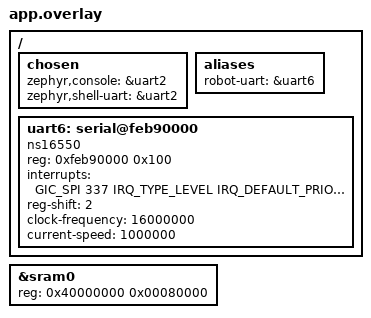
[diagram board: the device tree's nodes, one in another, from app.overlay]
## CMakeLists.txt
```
cmake_minimum_required(VERSION 3.20.0)
find_package(Zephyr REQUIRED HINTS $ENV{ZEPHYR_BASE})
project(orangepi_robot_control)

target_include_directories(app PRIVATE ${CMAKE_CURRENT_LIST_DIR}/../../protocol)

target_sources(app PRIVATE
  src/main.c
  src/ivc_transport.c
  src/robot_config_receiver.c
  src/feetech_bus.c
  src/robot_controller.c
  src/resettable_watchdog.c
)
```

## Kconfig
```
mainmenu "Orange Pi robot control"

source "Kconfig.zephyr"

config ROBOT_STATUS_EVERY_MESSAGES
	int "Valid IVC messages per combined status report"
	default 60
	range 0 1000000
	help
	  Print one combined receive, control-rate and latest-perception status
	  after this many valid IVC messages. Set to 0 to disable the report.

config ROBOT_CONTROL_ALIVE_LOG
	bool "Print an independent robot-control alive heartbeat"
	default n
	help
	  Print ZEPHYR_ROBOT_CONTROL_ALIVE every 10 seconds even when no IVC
	  messages arrive. The combined message-count status is normally enough.
```

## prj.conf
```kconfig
CONFIG_PRINTK=y
CONFIG_SERIAL=y
CONFIG_UART_NS16550=y
CONFIG_UART_NS16550_ACCESS_WORD_ONLY=y
CONFIG_MAIN_STACK_SIZE=8192
CONFIG_SYSTEM_WORKQUEUE_STACK_SIZE=4096
CONFIG_SYS_CLOCK_EXISTS=y
CONFIG_ARM_ARCH_TIMER=y
CONFIG_AXIVC=y
CONFIG_AXIVC_AXVISOR_HVC=y
CONFIG_AXIVC_FALLBACK_POLL_MS=1
CONFIG_AXIVC_MAX_CHANNELS=1

CONFIG_ROBOT_STATUS_EVERY_MESSAGES=60
CONFIG_ROBOT_CONTROL_ALIVE_LOG=n

# Keep exceptional watchdog, controller and UART diagnostics deferred rather
# than synchronously writing the virtual console while a controller/UART lock
# is held. Routine Feetech and arm-work sampling is intentionally disabled.
CONFIG_LOG=y
CONFIG_LOG_MODE_DEFERRED=y
CONFIG_LOG_DEFAULT_LEVEL=1
CONFIG_LOG_RUNTIME_DEFAULT_LEVEL=4
CONFIG_LOG_BUFFER_SIZE=8192
CONFIG_LOG_PROCESS_THREAD=y
CONFIG_LOG_PROCESS_THREAD_STACK_SIZE=2048
CONFIG_LOG_PRINTK=n

# Keep the interactive terminal on AxVisor's AArch64 PL011 virtual console.
# UART6 remains dedicated to the 1 Mbps Feetech bus selected by robot-uart.
CONFIG_SHELL=y
CONFIG_SHELL_MINIMAL=y
CONFIG_SHELL_BACKEND_SERIAL=y
CONFIG_SHELL_PROMPT_UART="zephyr:~$ "
CONFIG_KERNEL_SHELL=y
CONFIG_DEVICE_SHELL=y
```

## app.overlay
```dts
/ {
	chosen {
		/* AxVisor owns the physical UART2 console and turns the host-selected
		 * UART2 into an emulated console for this virtualized guest, so Zephyr
		 * must keep using the board's default uart2 node.  Do not list UART2 in
		 * the guest passthrough set: only UART6 is passed through physically.
		 */
		zephyr,console = &uart2;
		zephyr,shell-uart = &uart2;
	};

	aliases {
		robot-uart = &uart6;
	};

	uart6: serial@feb90000 {
		compatible = "ns16550";
		reg = <0xfeb90000 0x100>;
		interrupts = <GIC_SPI 337 IRQ_TYPE_LEVEL IRQ_DEFAULT_PRIORITY>;
		reg-shift = <2>;
		/* U-Boot prepares the UART6 fractional parent at 16 MHz.  An
		 * integer divisor of one then gives the Feetech bus' exact 1 Mbps
		 * rate, matching the board's working Linux configuration.
		 */
		clock-frequency = <16000000>;
		current-speed = <1000000>;
		status = "okay";
	};
};

/* The fixed control workload needs no dynamic bulk RAM.  Keep Zephyr's own
 * page-frame ontology small; AxVisor still reserves a 128 MiB isolation slot.
 */
&sram0 {
	reg = <0x40000000 0x00080000>;
};
```

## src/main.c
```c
/* SPDX-License-Identifier: Apache-2.0 */

#include "feetech_bus.h"
#include "ivc_transport.h"
#include "perception_result_v2.h"
#include "resettable_watchdog.h"
#include "robot_config_receiver.h"
#include "robot_controller.h"

#include <zephyr/device.h>
#include <zephyr/drivers/uart.h>
#include <zephyr/kernel.h>
#include <zephyr/logging/log.h>
#include <zephyr/sys/printk.h>
#include <zephyr/sys/util.h>

#include <errno.h>
#include <stdbool.h>
#include <stdint.h>

#define ROBOT_UART_NODE DT_ALIAS(robot_uart)
#define ARM_INTERPOLATION_PERIOD_MS 50U
#define IVC_IDLE_POLL_MS 1U
#define IVC_RECONNECT_IDLE_MS 1500U
#define STARTUP_SETTLE_MS 30000U
#define HEARTBEAT_MS 10000U
#define FEETECH_UART_BAUD 1000000U
#define SLOW_CONTROLLER_LOCK_MS 5U
#define SLOW_CONTROL_PROCESS_MS 20U

LOG_MODULE_REGISTER(robot_control_diag, LOG_LEVEL_DBG);

static const struct device *const robot_uart = DEVICE_DT_GET(ROBOT_UART_NODE);
static struct robot_controller controller;
static struct resettable_watchdog input_watchdog;
static struct k_timer arm_timer;
static struct k_work arm_work;
K_MUTEX_DEFINE(controller_lock);

static int64_t next_arm_deadline_ms;
static uint64_t arm_cycles;
static uint32_t max_arm_timer_late_ms;

BUILD_ASSERT(sizeof(struct perception_result_v2) == 48U);
BUILD_ASSERT(sizeof(struct robot_config_message_v1) == 48U);

static int receive_initial_config(struct robot_ivc *ivc,
				  struct robot_config_receiver *receiver,
				  struct robot_runtime_config_v1 *config)
{
	uint64_t idle_polls = 0U;

	printk("ZEPHYR_ROBOT_CONFIG_WAIT source=axvisor-ivc\n");
	for (;;) {
		struct robot_config_message_v1 message = {0};
		struct robot_config_message_v1 response = {0};
		size_t length = 0U;
		int status = robot_ivc_try_receive(ivc, &message, sizeof(message), &length);

		if (status == -EAGAIN) {
			if (++idle_polls % 1000U == 0U) {
				printk("ZEPHYR_ROBOT_CONFIG_WAIT polls=%llu\n", idle_polls);
			}
			k_msleep(IVC_IDLE_POLL_MS);
			continue;
		}
		if (status != 0) {
			printk("ZEPHYR_ROBOT_CONFIG_FAILED reason=receive status=%d\n",
			       status);
			return status;
		}
		if (!robot_config_is_message(&message, length)) {
			printk("ZEPHYR_ROBOT_CONFIG_DROP reason=expected-config len=%zu\n",
			       length);
			continue;
		}

		bool applied = false;
		robot_config_receiver_handle(receiver, &message, &response, config,
					     &applied);
		if (applied) {
			robot_config_receiver_mark_applied(receiver);
		}
		status = robot_ivc_send(ivc, &response, sizeof(response), 500);
		if (status != 0) {
			printk("ZEPHYR_ROBOT_CONFIG_FAILED reason=ack-send chunk=%u "
			       "status=%d\n", message.chunk_index, status);
			return status;
		}
		if (response.type == ROBOT_CONFIG_REJECTED) {
			printk("ZEPHYR_ROBOT_CONFIG_REJECTED session=%u chunk=%u "
			       "status=%u expected=%u\n", response.session_id,
			       response.chunk_index, response.status,
			       response.chunk_count);
		} else if (applied) {
			printk("ZEPHYR_ROBOT_CONFIG_APPLIED session=%u chunks=%u "
			       "crc=0x%08x speed_level=%u\n", response.session_id,
			       response.chunk_count, response.config_crc32,
			       config->motion_speed_level);
			return 0;
		} else {
			printk("ZEPHYR_ROBOT_CONFIG_ACK session=%u chunk=%u "
			       "next=%u\n", response.session_id,
			       response.chunk_index, response.chunk_count);
		}
	}
}

static void input_watchdog_handler(void *context)
{
	struct robot_controller *robot = context;
	const int64_t now_ms = k_uptime_get();
	const int64_t lock_started_ms = now_ms;

	LOG_DBG("ZEPHYR_DIAG component=watchdog event=handler-enter uptime_ms=%lld",
		now_ms);
	k_mutex_lock(&controller_lock, K_FOREVER);
	const int64_t lock_wait_ms = k_uptime_get() - lock_started_ms;
	const bool expired = robot_controller_input_timeout(robot, now_ms);
	if (!expired && robot->have_input) {
		/* An expiry work item can already be queued when a new frame resets
		 * the timer.  Recompute the remaining time so that this stale work
		 * item cannot cancel the new frame's deadline.  This also makes an
		 * early, tick-rounded callback harmless.
		 */
		const int64_t elapsed_ms = MAX(now_ms - robot->last_input_ms, 0);
		const uint32_t remaining_ms =
			ROBOT_INPUT_TIMEOUT_MS -
			(uint32_t)MIN(elapsed_ms, ROBOT_INPUT_TIMEOUT_MS - 1U);
		resettable_watchdog_restart(&input_watchdog, remaining_ms);
	}
	k_mutex_unlock(&controller_lock);
	LOG_DBG("ZEPHYR_DIAG component=watchdog event=handler-exit expired=%u "
		"lock_wait_ms=%lld elapsed_ms=%lld",
		expired, lock_wait_ms, k_uptime_get() - now_ms);
}

static void arm_work_handler(struct k_work *work)
{
	ARG_UNUSED(work);
	const int64_t now_ms = k_uptime_get();
	k_mutex_lock(&controller_lock, K_FOREVER);
	if (now_ms > next_arm_deadline_ms) {
		max_arm_timer_late_ms =
			MAX(max_arm_timer_late_ms,
			    (uint32_t)(now_ms - next_arm_deadline_ms));
	}
	do {
		next_arm_deadline_ms += ARM_INTERPOLATION_PERIOD_MS;
	} while (next_arm_deadline_ms <= now_ms);

	robot_controller_arm_tick(&controller, now_ms);
	++arm_cycles;
	k_mutex_unlock(&controller_lock);
}

static void arm_timer_expiry(struct k_timer *timer)
{
	ARG_UNUSED(timer);
	(void)k_work_submit(&arm_work);
}

static bool valid_result(const struct perception_result_v2 *result)
{
	return result->magic == PERCEPTION_MAGIC &&
	       result->version == PERCEPTION_VERSION &&
	       result->frame_width > 0U && result->frame_height > 0U;
}

int main(void)
{
	struct feetech_bus bus = {0};
	struct robot_ivc ivc = {0};
	struct robot_config_receiver config_receiver;
	struct robot_runtime_config_v1 runtime_config;
	uint16_t initial_arm[FEETECH_ARM_COUNT];
	uint64_t received = 0U;
	uint64_t processed = 0U;
	uint64_t invalid = 0U;
	uint64_t heartbeat = 0U;
	int64_t next_heartbeat_ms;
	bool status_window_active = false;
	int64_t status_window_started_ms = 0;
	uint64_t status_window_started_received = 0U;
	uint64_t status_window_started_processed = 0U;
	int status;

	printk("ZEPHYR_ROBOT_CONTROL_START protocol=2 source=axvisor-ivc uart=uart6\n");
	printk("ZEPHYR_TIMER_READY driver=arm_arch_timer tick_hz=%u\n",
	       CONFIG_SYS_CLOCK_TICKS_PER_SEC);
	printk("ZEPHYR_ROBOT_CONTROL_WAIT settle_ms=%u\n", STARTUP_SETTLE_MS);
	const int64_t startup_started_ms = k_uptime_get();
	k_msleep(STARTUP_SETTLE_MS);
	const int64_t startup_elapsed_ms = k_uptime_get() - startup_started_ms;
	printk("ZEPHYR_TIMER_WAKE phase=startup requested_ms=%u actual_ms=%lld\n",
	       STARTUP_SETTLE_MS, startup_elapsed_ms);

	status = feetech_bus_init(&bus, robot_uart);
	if (status != 0) {
		printk("ZEPHYR_ROBOT_CONTROL_FAILED reason=uart6-not-ready status=%d\n",
		       status);
		return 1;
	}
	const struct uart_config config = {
		/* 16 MHz input / (16 * DLL=1) = 1 Mbps. */
		.baudrate = FEETECH_UART_BAUD,
		.parity = UART_CFG_PARITY_NONE,
		.stop_bits = UART_CFG_STOP_BITS_1,
		.data_bits = UART_CFG_DATA_BITS_8,
		.flow_ctrl = UART_CFG_FLOW_CTRL_NONE,
	};
	status = uart_configure(robot_uart, &config);
	if (status != 0) {
		printk("ZEPHYR_ROBOT_CONTROL_FAILED reason=uart6-config status=%d\n",
		       status);
		return 1;
	}
	printk("ZEPHYR_UART6_READY clock_hz=16000000 baud=1000000 divisor=1 dlf=0\n");

	status = feetech_configure_wheels(&bus);
	if (status != 0) {
		return 1;
	}
	status = feetech_configure_arm(&bus, initial_arm);
	if (status != 0) {
		feetech_stop_wheels(&bus, "ARM_INIT_FAILED_STOP");
		printk("ZEPHYR_ROBOT_CONTROL_FAILED reason=arm-config status=%d\n", status);
		return 1;
	}
	status = robot_ivc_subscribe(&ivc);
	if (status != 0) {
		feetech_stop_wheels(&bus, "IVC_FAILED_STOP");
		printk("ZEPHYR_ROBOT_CONTROL_FAILED reason=ivc-subscribe status=%d\n", status);
		return 1;
	}
	robot_config_receiver_init(&config_receiver);
	status = receive_initial_config(&ivc, &config_receiver, &runtime_config);
	if (status != 0) {
		feetech_stop_wheels(&bus, "CONFIG_FAILED_STOP");
		feetech_arm_torque_off(&bus);
		(void)robot_ivc_close(&ivc);
		return 1;
	}
	status = robot_controller_init(&controller, &bus, &runtime_config);
	if (status != 0) {
		feetech_stop_wheels(&bus, "CONTROLLER_INIT_FAILED_STOP");
		(void)robot_ivc_close(&ivc);
		return 1;
	}
	resettable_watchdog_init(&input_watchdog, input_watchdog_handler,
				 &controller);
	k_work_init(&arm_work, arm_work_handler);
	k_timer_init(&arm_timer, arm_timer_expiry, NULL);
	next_arm_deadline_ms = k_uptime_get() + ARM_INTERPOLATION_PERIOD_MS;
	k_timer_start(&arm_timer, K_MSEC(ARM_INTERPOLATION_PERIOD_MS),
		      K_MSEC(ARM_INTERPOLATION_PERIOD_MS));
	printk("ZEPHYR_ROBOT_CONTROL_READY source=axvisor-ivc arm_period_ms=%u "
	       "ivc_poll_ms=%u watchdog_ms=%u watchdog=resettable-one-shot\n",
	       ARM_INTERPOLATION_PERIOD_MS, IVC_IDLE_POLL_MS,
	       ROBOT_INPUT_TIMEOUT_MS);
	next_heartbeat_ms = k_uptime_get() + HEARTBEAT_MS;

	for (;;) {
		struct perception_result_v2 newest;
		bool have_newest = false;
		bool transport_disconnected = false;
		const uint64_t received_before_poll = received;
		const uint64_t processed_before_poll = processed;

		for (;;) {
			union {
				struct perception_result_v2 perception;
				struct robot_config_message_v1 config;
				uint8_t bytes[ROBOT_CONFIG_MESSAGE_SIZE];
			} message = {0};
			size_t length = 0U;
			status = robot_ivc_try_receive(&ivc, message.bytes,
					       sizeof(message.bytes),
					       &length);
			if (status == -EAGAIN) {
				break;
			}
			if (status != 0) {
				++invalid;
				printk("ZEPHYR_IVC_DROP status=%d len=%zu invalid=%llu\n",
				       status, length,
				       invalid);
				transport_disconnected = true;
				break;
			}
			if (robot_config_is_message(message.bytes, length)) {
				struct robot_config_message_v1 response = {0};
				if (message.config.type == ROBOT_CONTROL_FINISH) {
					k_mutex_lock(&controller_lock, K_FOREVER);
					robot_controller_control_result(&controller,
						config_receiver.applied_session_id,
						config_receiver.applied_crc32, &message.config, &response);
					k_mutex_unlock(&controller_lock);
					/* The main loop is the sole reverse-ring producer. */
					status = robot_ivc_send(&ivc, &response, sizeof(response), 0);
					if (status != 0 && status != -EAGAIN && status != -ETIMEDOUT) {
						printk("ZEPHYR_CONTROL_RESULT_SEND_FAILED status=%d\n", status);
					}
					continue;
				}
				struct robot_runtime_config_v1 candidate = {0};
				bool applied = false;
				bool ready = true;

				if (message.config.type == ROBOT_CONFIG_BEGIN) {
					k_mutex_lock(&controller_lock, K_FOREVER);
					ready = robot_controller_prepare_config_update(&controller);
					k_mutex_unlock(&controller_lock);
				}
				if (!ready) {
					robot_config_make_rejected(
						&message.config, &response,
						ROBOT_CONFIG_STATUS_BUSY,
						config_receiver.expected_chunk);
				} else {
					robot_config_receiver_handle(
						&config_receiver, &message.config, &response,
						&candidate, &applied);
				}
				if (applied) {
					k_mutex_lock(&controller_lock, K_FOREVER);
					status = robot_controller_apply_config(&controller,
									       &candidate);
					k_mutex_unlock(&controller_lock);
					if (status != 0) {
						robot_config_make_rejected(
							&message.config, &response,
							ROBOT_CONFIG_STATUS_BUSY,
								config_receiver.expected_chunk);
						applied = false;
					} else {
						robot_config_receiver_mark_applied(
							&config_receiver);
					}
				}
				status = robot_ivc_send(&ivc, &response,
							sizeof(response), 500);
				if (status != 0) {
					printk("ZEPHYR_ROBOT_CONFIG_FAILED reason=ack-send "
					       "chunk=%u status=%d\n",
					       message.config.chunk_index, status);
				} else if (applied) {
					printk("ZEPHYR_ROBOT_CONFIG_APPLIED session=%u "
					       "chunks=%u crc=0x%08x speed_level=%u "
					       "restart=1\n", response.session_id,
					       response.chunk_count, response.config_crc32,
					       candidate.motion_speed_level);
				} else if (response.type == ROBOT_CONFIG_REJECTED) {
					printk("ZEPHYR_ROBOT_CONFIG_REJECTED session=%u "
					       "chunk=%u status=%u expected=%u\n",
					       response.session_id, response.chunk_index,
					       response.status, response.chunk_count);
				} else {
					printk("ZEPHYR_ROBOT_CONFIG_ACK session=%u chunk=%u "
					       "next=%u restart=1\n", response.session_id,
					       response.chunk_index, response.chunk_count);
				}
				continue;
			}
			if (length != sizeof(message.perception) ||
			    !valid_result(&message.perception)) {
				++invalid;
				printk("ZEPHYR_IVC_DROP status=0 len=%zu payload_seq=%llu "
				       "invalid=%llu\n", length,
				       message.perception.sequence, invalid);
				continue;
			}
			newest = message.perception;
			have_newest = true;
			++received;
		}

		const int64_t now_ms = k_uptime_get();
		if (have_newest) {
			if (!status_window_active) {
				status_window_active = true;
				status_window_started_ms = now_ms;
				status_window_started_received = received_before_poll;
				status_window_started_processed = processed_before_poll;
			}
			const int64_t control_started_ms = k_uptime_get();
			k_mutex_lock(&controller_lock, K_FOREVER);
			const int64_t control_lock_wait_ms =
				k_uptime_get() - control_started_ms;
			robot_controller_process_perception(&controller, &newest,
						    now_ms);
			++processed;
			k_mutex_unlock(&controller_lock);
			const int64_t control_elapsed_ms =
				k_uptime_get() - control_started_ms;
			if (control_lock_wait_ms >= SLOW_CONTROLLER_LOCK_MS ||
			    control_elapsed_ms >= SLOW_CONTROL_PROCESS_MS) {
				LOG_DBG_RATELIMIT_RATE(
					1000,
					"ZEPHYR_DIAG component=control event=slow seq=%llu "
					"lock_wait_ms=%lld elapsed_ms=%lld",
					newest.sequence, control_lock_wait_ms,
					control_elapsed_ms);
			}
			resettable_watchdog_restart(&input_watchdog,
						 ROBOT_INPUT_TIMEOUT_MS);
			const uint64_t status_messages =
				received - status_window_started_received;
			if (CONFIG_ROBOT_STATUS_EVERY_MESSAGES > 0 &&
			    status_messages >= CONFIG_ROBOT_STATUS_EVERY_MESSAGES) {
				const uint64_t window_ms = (uint64_t)MAX(
					now_ms - status_window_started_ms, 1);
				const uint64_t status_processed =
					processed - status_window_started_processed;
				const uint64_t coalesced =
					status_messages - MIN(status_messages, status_processed);
				const uint64_t rx_fps_centi =
					status_messages * 100000U / window_ms;
				const uint64_t control_fps_centi =
					status_processed * 100000U / window_ms;

				k_mutex_lock(&controller_lock, K_FOREVER);
				printk("ZEPHYR_CONTROL_STATUS messages=%llu "
				       "window_s=%llu.%02llu rx_fps=%llu.%02llu "
				       "control_fps=%llu.%02llu coalesced=%llu "
				       "seq=%llu received=%llu processed=%llu invalid=%llu "
				       "state=%s arm_cycles=%llu max_arm_timer_late_ms=%u "
				       "frame=%ux%u ball_visible=%u "
				       "ball_confidence_milli=%u ball_center=%u,%u "
				       "ball_box=%ux%u bucket_visible=%u "
				       "bucket_center=%u,%u bucket_box=%ux%u\n",
				       status_messages, window_ms / 1000U,
				       (window_ms % 1000U) / 10U, rx_fps_centi / 100U,
				       rx_fps_centi % 100U, control_fps_centi / 100U,
				       control_fps_centi % 100U, coalesced, newest.sequence,
				       received, processed, invalid,
				       robot_controller_state_name(&controller), arm_cycles,
				       max_arm_timer_late_ms, newest.frame_width,
				       newest.frame_height,
				       (newest.flags & PERCEPTION_TARGET_VISIBLE) != 0U,
				       newest.confidence_milli, newest.center_x,
				       newest.center_y, newest.box_width, newest.box_height,
				       (newest.flags & PERCEPTION_BUCKET_VISIBLE) != 0U,
				       newest.bucket_center_x, newest.bucket_center_y,
				       newest.bucket_box_width, newest.bucket_box_height);
				k_mutex_unlock(&controller_lock);

				status_window_started_ms = now_ms;
				status_window_started_received = received;
				status_window_started_processed = processed;
			}
		}
		if (!have_newest) {
			bool reconnect = false;
			k_mutex_lock(&controller_lock, K_FOREVER);
			if ((transport_disconnected ||
			     (received > 0U &&
			      now_ms - controller.last_input_ms >= IVC_RECONNECT_IDLE_MS))) {
				reconnect = robot_controller_prepare_config_update(&controller);
			}
			k_mutex_unlock(&controller_lock);
			if (reconnect) {
				resettable_watchdog_stop(&input_watchdog);
				printk("ZEPHYR_IVC_RECONNECT reason=%s elapsed_ms=%lld\n",
				       transport_disconnected ? "transport-error" : "publisher-idle",
				       now_ms - controller.last_input_ms);
				(void)robot_ivc_close(&ivc);
				status = robot_ivc_subscribe(&ivc);
				if (status != 0) {
					printk("ZEPHYR_ROBOT_CONTROL_FAILED reason=ivc-reconnect "
					       "status=%d\n", status);
					return 1;
				}
				robot_config_receiver_init(&config_receiver);
				status = receive_initial_config(&ivc, &config_receiver,
							&runtime_config);
				if (status != 0) {
					printk("ZEPHYR_ROBOT_CONTROL_FAILED reason=config-reconnect "
					       "status=%d\n", status);
					return 1;
				}
				k_mutex_lock(&controller_lock, K_FOREVER);
				status = robot_controller_apply_config(&controller,
							       &runtime_config);
				k_mutex_unlock(&controller_lock);
				if (status != 0) {
					printk("ZEPHYR_ROBOT_CONTROL_FAILED reason=config-apply-reconnect "
					       "status=%d\n", status);
					return 1;
				}
				printk("ZEPHYR_IVC_RECONNECTED config_crc=0x%08x\n",
				       robot_config_crc32(&runtime_config,
						  sizeof(runtime_config)));
				status_window_active = false;
				continue;
			}
		}
		if (IS_ENABLED(CONFIG_ROBOT_CONTROL_ALIVE_LOG) &&
		    k_uptime_get() >= next_heartbeat_ms) {
			++heartbeat;
			k_mutex_lock(&controller_lock, K_FOREVER);
			printk("ZEPHYR_ROBOT_CONTROL_ALIVE heartbeat=%llu state=%s "
			       "pick_cycles=%llu received=%llu processed=%llu invalid=%llu "
			       "arm_cycles=%llu max_arm_timer_late_ms=%u\n", heartbeat,
			       robot_controller_state_name(&controller),
			       controller.completed_cycles, received, processed, invalid,
			       arm_cycles, max_arm_timer_late_ms);
			k_mutex_unlock(&controller_lock);
			next_heartbeat_ms = k_uptime_get() + HEARTBEAT_MS;
		}

		/* The current AxVisor IVC transport exposes a shared ring rather than
		 * a Zephyr waitable object.  Poll it at 1 ms while idle; this bounds
		 * receive latency without tying it to the 50 ms arm timer.
		 */
		if (!have_newest) {
			k_msleep(IVC_IDLE_POLL_MS);
		} else {
			k_yield();
		}
	}
}
```

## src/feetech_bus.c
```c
/* SPDX-License-Identifier: Apache-2.0 */

#include "feetech_bus.h"

#include <zephyr/drivers/uart.h>
#include <zephyr/kernel.h>
#include <zephyr/logging/log.h>
#include <zephyr/sys/printk.h>
#include <zephyr/sys/util.h>

#include <errno.h>
#include <stdbool.h>
#include <string.h>

#define FEETECH_BROADCAST_ID 0xfeU
#define FEETECH_INST_READ 0x02U
#define FEETECH_INST_SYNC_WRITE 0x83U

#define FEETECH_P_COEFFICIENT 21U
#define FEETECH_D_COEFFICIENT 22U
#define FEETECH_I_COEFFICIENT 23U
#define FEETECH_OPERATING_MODE 33U
#define FEETECH_TORQUE_ENABLE 40U
#define FEETECH_ACCELERATION 41U
#define FEETECH_GOAL_POSITION 42U
#define FEETECH_GOAL_VELOCITY 46U
#define FEETECH_PRESENT_POSITION 56U

#define FEETECH_POSITION_MODE 0U
#define FEETECH_VELOCITY_MODE 1U
#define FEETECH_STATUS_OVERLOAD 0x20U
#define FEETECH_RX_TIMEOUT_MS 120U
#define FEETECH_TX_TIMEOUT_MS 20U
LOG_MODULE_REGISTER(feetech_diag, LOG_LEVEL_DBG);

static const uint8_t arm_ids[FEETECH_ARM_COUNT] = {1U, 2U, 3U, 4U, 5U, 6U};
static const uint8_t wheel_ids[] = {7U, 8U, 9U};

static size_t flush_input(struct feetech_bus *bus)
{
	uint8_t byte;
	size_t count = 0U;

	while (uart_poll_in(bus->uart, &byte) == 0) {
		++count;
	}
	return count;
}

static int wait_tx_idle(struct feetech_bus *bus)
{
	const int64_t deadline_ms = k_uptime_get() + FEETECH_TX_TIMEOUT_MS;

	while (k_uptime_get() < deadline_ms) {
		const int ready = uart_irq_tx_complete(bus->uart);

		if (ready > 0) {
			return 0;
		}
		if (ready < 0) {
			return ready;
		}
		k_busy_wait(10U);
	}
	LOG_DBG("ZEPHYR_DIAG component=feetech event=tx-idle-timeout "
		"timeout_ms=%u uptime_ms=%lld",
		FEETECH_TX_TIMEOUT_MS, k_uptime_get());
	return -ETIMEDOUT;
}

static int send_bytes(struct feetech_bus *bus, const uint8_t *bytes, size_t length)
{
	for (size_t index = 0; index < length; ++index) {
		const int result = wait_tx_idle(bus);

		if (result != 0) {
			return result;
		}
		/* This application binds UART6 to the ns16550 driver.  Wait until
		 * THRE/TEMT is observed before entering its unbounded poll_out loop.
		 */
		uart_poll_out(bus->uart, bytes[index]);
	}
	return 0;
}

static int send_packet(struct feetech_bus *bus, uint8_t id, uint8_t instruction,
		       const uint8_t *params, size_t param_count)
{
	uint8_t packet[32];
	uint16_t sum;

	if (param_count + 6U > sizeof(packet)) {
		return -EMSGSIZE;
	}
	packet[0] = 0xffU;
	packet[1] = 0xffU;
	packet[2] = id;
	packet[3] = (uint8_t)(param_count + 2U);
	packet[4] = instruction;
	memcpy(&packet[5], params, param_count);
	sum = id + packet[3] + instruction;
	for (size_t index = 0; index < param_count; ++index) {
		sum += params[index];
	}
	packet[5U + param_count] = (uint8_t)(~sum);
	return send_bytes(bus, packet, param_count + 6U);
}

static int read_byte_until(struct feetech_bus *bus, uint8_t *byte, int64_t deadline_ms)
{
	while (k_uptime_get() < deadline_ms) {
		if (uart_poll_in(bus->uart, byte) == 0) {
			return 0;
		}
		k_busy_wait(100U);
	}
	return -ETIMEDOUT;
}

static int receive_status(struct feetech_bus *bus, uint8_t expected_id,
			  uint8_t *params, size_t capacity, size_t *length,
			  uint8_t *status)
{
	const int64_t deadline_ms = k_uptime_get() + FEETECH_RX_TIMEOUT_MS;
	uint8_t previous = 0U;
	uint8_t byte = 0U;

	while (read_byte_until(bus, &byte, deadline_ms) == 0) {
		if (previous == 0xffU && byte == 0xffU) {
			break;
		}
		previous = byte;
	}
	if (previous != 0xffU || byte != 0xffU) {
		return -ETIMEDOUT;
	}

	uint8_t id;
	uint8_t packet_length;
	uint8_t error;
	if (read_byte_until(bus, &id, deadline_ms) != 0 ||
	    read_byte_until(bus, &packet_length, deadline_ms) != 0 ||
	    read_byte_until(bus, &error, deadline_ms) != 0) {
		return -ETIMEDOUT;
	}
	if (id != expected_id || packet_length < 2U ||
	    packet_length - 2U > capacity) {
		return -EPROTO;
	}

	const size_t param_count = packet_length - 2U;
	uint16_t sum = id + packet_length + error;
	for (size_t index = 0; index < param_count; ++index) {
		if (read_byte_until(bus, &params[index], deadline_ms) != 0) {
			return -ETIMEDOUT;
		}
		sum += params[index];
	}
	uint8_t checksum;
	if (read_byte_until(bus, &checksum, deadline_ms) != 0) {
		return -ETIMEDOUT;
	}
	if (checksum != (uint8_t)(~sum)) {
		return -EBADMSG;
	}
	*length = param_count;
	*status = error;
	return 0;
}

static int transact(struct feetech_bus *bus, uint8_t id, uint8_t instruction,
		    const uint8_t *params, size_t param_count, uint8_t *reply,
		    size_t capacity, size_t *reply_length, uint8_t allowed_status,
		    uint8_t *actual_status)
{
	uint8_t status = 0U;
	int result;
	(void)flush_input(bus);
	result = send_packet(bus, id, instruction, params, param_count);
	if (result != 0 || id == FEETECH_BROADCAST_ID) {
		return result;
	}
	result = receive_status(bus, id, reply, capacity, reply_length, &status);
	if (actual_status != NULL) {
		*actual_status = status;
	}
	if (result == 0 && (status & (uint8_t)~allowed_status) != 0U) {
		result = -EIO;
	}
	return result;
}

static int read_u16(struct feetech_bus *bus, uint8_t id, uint8_t address,
		    uint16_t *value, uint8_t allowed_status, uint8_t *status)
{
	const uint8_t params[] = {address, 2U};
	uint8_t reply[4];
	size_t reply_length = 0U;
	int result;

	result = transact(bus, id, FEETECH_INST_READ, params, sizeof(params), reply,
			sizeof(reply), &reply_length, allowed_status, status);
	if (result != 0 || reply_length != 2U) {
		return result != 0 ? result : -EPROTO;
	}
	*value = (uint16_t)reply[0] | ((uint16_t)reply[1] << 8);
	return 0;
}

int feetech_read_wheel_feedback(struct feetech_bus *bus, uint8_t index,
                                int16_t *velocity, uint16_t *position)
{
    if (index >= ARRAY_SIZE(wheel_ids) || velocity == NULL || position == NULL) return -EINVAL;
    const uint8_t params[] = {FEETECH_PRESENT_POSITION, 4U};
    uint8_t reply[4];
    size_t length = 0U;
    int result = transact(bus, wheel_ids[index], FEETECH_INST_READ, params, sizeof(params),
                          reply, sizeof(reply), &length, 0U, NULL);
    if (result != 0) return result;
    if (length != sizeof(reply)) return -EPROTO;
    const uint16_t raw_position = (uint16_t)reply[0] | ((uint16_t)reply[1] << 8);
    // Normalize sign-magnitude position to the 12-bit encoder circle.
    *position = (uint16_t)((raw_position & 0x8000U) ?
                          0U - (raw_position & 0x7fffU) : raw_position) & 0x0fffU;
    uint16_t raw = (uint16_t)reply[2] | ((uint16_t)reply[3] << 8);
    *velocity = (raw & 0x8000U) ? -(int16_t)(raw & 0x7fffU) : (int16_t)raw;
    return 0;
}

static int sync_write_u16(struct feetech_bus *bus, uint8_t address,
			  const uint8_t *ids, const uint16_t *values, size_t count)
{
	uint8_t params[2U + 3U * FEETECH_ARM_COUNT];
	uint8_t reply[1];
	size_t reply_length = 0U;

	if (count > FEETECH_ARM_COUNT) {
		return -EINVAL;
	}
	params[0] = address;
	params[1] = 2U;
	for (size_t index = 0; index < count; ++index) {
		params[2U + index * 3U] = ids[index];
		params[3U + index * 3U] = (uint8_t)(values[index] & 0xffU);
		params[4U + index * 3U] = (uint8_t)(values[index] >> 8);
	}
	return transact(bus, FEETECH_BROADCAST_ID, FEETECH_INST_SYNC_WRITE, params,
			2U + count * 3U, reply, sizeof(reply), &reply_length, 0U, NULL);
}

static int sync_write_u8(struct feetech_bus *bus, uint8_t address,
			 const uint8_t *ids, uint8_t value, size_t count)
{
	uint8_t params[2U + 2U * FEETECH_ARM_COUNT];
	uint8_t reply[1];
	size_t reply_length = 0U;

	if (count > FEETECH_ARM_COUNT) {
		return -EINVAL;
	}
	params[0] = address;
	params[1] = 1U;
	for (size_t index = 0; index < count; ++index) {
		params[2U + index * 2U] = ids[index];
		params[3U + index * 2U] = value;
	}
	return transact(bus, FEETECH_BROADCAST_ID, FEETECH_INST_SYNC_WRITE, params,
			2U + count * 2U, reply, sizeof(reply), &reply_length, 0U, NULL);
}

static uint16_t encode_velocity(int32_t value)
{
	const uint32_t absolute = value < 0 ? (uint32_t)(-value) : (uint32_t)value;
	uint16_t magnitude = (uint16_t)MIN(absolute, 0x7fffU);

	return (value < 0 ? 0x8000U : 0U) | magnitude;
}

int feetech_bus_init(struct feetech_bus *bus, const struct device *uart)
{
	if (bus == NULL || uart == NULL || !device_is_ready(uart)) {
		return -ENODEV;
	}
	bus->uart = uart;
	return 0;
}

int feetech_read_arm(struct feetech_bus *bus,
		     uint16_t positions[FEETECH_ARM_COUNT], uint8_t *gripper_status)
{
	for (size_t index = 0; index < FEETECH_ARM_COUNT; ++index) {
		uint8_t status = 0U;
		const uint8_t allowed = index + 1U == FEETECH_ARM_COUNT ?
					FEETECH_STATUS_OVERLOAD : 0U;
		int result = read_u16(bus, arm_ids[index], FEETECH_PRESENT_POSITION,
				      &positions[index], allowed, &status);

		if (result != 0) {
			printk("ZEPHYR_FEETECH_ERROR op=read-position id=%u status=%d\n",
			       arm_ids[index], result);
			return result;
		}
		if (index + 1U == FEETECH_ARM_COUNT && gripper_status != NULL) {
			*gripper_status = status;
		}
	}
	return 0;
}

int feetech_configure_wheels(struct feetech_bus *bus)
{
	int result;

	feetech_stop_wheels(bus, "INIT_STOP");
	result = sync_write_u8(bus, FEETECH_TORQUE_ENABLE, wheel_ids, 0U,
			       ARRAY_SIZE(wheel_ids));
	result = result == 0 ? sync_write_u8(bus, FEETECH_OPERATING_MODE,
					     wheel_ids, FEETECH_VELOCITY_MODE,
					     ARRAY_SIZE(wheel_ids)) : result;
	result = result == 0 ? sync_write_u8(bus, FEETECH_ACCELERATION, wheel_ids,
					     80U, ARRAY_SIZE(wheel_ids)) : result;
	result = result == 0 ? sync_write_u8(bus, FEETECH_TORQUE_ENABLE, wheel_ids,
					     1U, ARRAY_SIZE(wheel_ids)) : result;
	if (result != 0) {
		feetech_stop_wheels(bus, "INIT_FAILED_STOP");
		printk("ZEPHYR_FEETECH_ERROR op=configure-wheels status=%d\n", result);
		return result;
	}
	feetech_stop_wheels(bus, "WHEELS_READY_STOP");
	printk("ZEPHYR_WHEELS_READY ids=7,8,9 mode=velocity acceleration=80\n");
	return 0;
}

void feetech_arm_torque_off(struct feetech_bus *bus)
{
	(void)sync_write_u8(bus, FEETECH_TORQUE_ENABLE, arm_ids, 0U,
			    FEETECH_ARM_COUNT);
}

int feetech_configure_arm(struct feetech_bus *bus,
			 uint16_t current[FEETECH_ARM_COUNT])
{
	int result = feetech_read_arm(bus, current, NULL);

	if (result != 0) {
		return result;
	}
	feetech_arm_torque_off(bus);
	result = sync_write_u8(bus, FEETECH_OPERATING_MODE, arm_ids,
			       FEETECH_POSITION_MODE, FEETECH_ARM_COUNT);
	result = result == 0 ? sync_write_u8(bus, FEETECH_P_COEFFICIENT, arm_ids,
					     16U, FEETECH_ARM_COUNT) : result;
	result = result == 0 ? sync_write_u8(bus, FEETECH_I_COEFFICIENT, arm_ids,
					     0U, FEETECH_ARM_COUNT) : result;
	result = result == 0 ? sync_write_u8(bus, FEETECH_D_COEFFICIENT, arm_ids,
					     32U, FEETECH_ARM_COUNT) : result;
	result = result == 0 ? sync_write_u8(bus, FEETECH_ACCELERATION, arm_ids,
					     80U, FEETECH_ARM_COUNT) : result;
	if (result != 0) {
		feetech_arm_torque_off(bus);
		printk("ZEPHYR_FEETECH_ERROR op=configure-arm status=%d\n", result);
		return result;
	}
	result = sync_write_u16(bus, FEETECH_GOAL_POSITION, arm_ids, current,
				FEETECH_ARM_COUNT);
	if (result != 0) {
		feetech_arm_torque_off(bus);
		return result;
	}
	k_msleep(20);
	result = sync_write_u8(bus, FEETECH_TORQUE_ENABLE, arm_ids, 1U,
			       FEETECH_ARM_COUNT);
	if (result != 0) {
		feetech_arm_torque_off(bus);
		return result;
	}
	printk("ZEPHYR_ARM_READY ids=1,2,3,4,5,6 seeded=current-position\n");
	return 0;
}

int feetech_send_arm_pose(struct feetech_bus *bus,
			 const uint16_t positions[FEETECH_ARM_COUNT])
{
	return sync_write_u16(bus, FEETECH_GOAL_POSITION, arm_ids, positions,
			      FEETECH_ARM_COUNT);
}

int feetech_send_diff_drive(struct feetech_bus *bus, int16_t left,
			    int16_t right, const char *label)
{
	const int32_t average = ((int32_t)left + right) / 2;
	const int32_t difference = (int32_t)right - left;
	const int32_t raw[] = {
		(-1355 * average + 995 * difference) / 100,
		(995 * difference) / 100,
		(1355 * average + 995 * difference) / 100,
	};
	uint16_t encoded[ARRAY_SIZE(wheel_ids)];

	for (size_t index = 0; index < ARRAY_SIZE(encoded); ++index) {
		encoded[index] = encode_velocity(CLAMP(raw[index], -3000, 3000));
	}
	int result = sync_write_u16(bus, FEETECH_GOAL_VELOCITY, wheel_ids, encoded,
				    ARRAY_SIZE(wheel_ids));
	printk("ZEPHYR_CONTROL command=%s diff=%d,%d wheels=%d,%d,%d status=%d\n",
	       label, left, right, (int)raw[0], (int)raw[1], (int)raw[2], result);
	return result;
}

void feetech_stop_wheels(struct feetech_bus *bus, const char *label)
{
	(void)feetech_send_diff_drive(bus, 0, 0, label);
}
```

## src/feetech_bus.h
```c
/* SPDX-License-Identifier: Apache-2.0 */

#ifndef ROBOT_FEETECH_BUS_H_
#define ROBOT_FEETECH_BUS_H_

#include <zephyr/device.h>

#include <stddef.h>
#include <stdint.h>

#define FEETECH_ARM_COUNT 6U

struct feetech_bus {
	const struct device *uart;
};

int feetech_bus_init(struct feetech_bus *bus, const struct device *uart);
int feetech_configure_wheels(struct feetech_bus *bus);
int feetech_configure_arm(struct feetech_bus *bus,
			 uint16_t current[FEETECH_ARM_COUNT]);
/* One bounded UART transaction; velocity uses the Feetech sign-magnitude format. */
int feetech_read_wheel_feedback(struct feetech_bus *bus, uint8_t index,
                                int16_t *velocity, uint16_t *position);
int feetech_read_arm(struct feetech_bus *bus,
		     uint16_t positions[FEETECH_ARM_COUNT],
		     uint8_t *gripper_status);
int feetech_send_arm_pose(struct feetech_bus *bus,
			 const uint16_t positions[FEETECH_ARM_COUNT]);
int feetech_send_diff_drive(struct feetech_bus *bus, int16_t left,
			    int16_t right, const char *label);
void feetech_stop_wheels(struct feetech_bus *bus, const char *label);
void feetech_arm_torque_off(struct feetech_bus *bus);

#endif /* ROBOT_FEETECH_BUS_H_ */
```

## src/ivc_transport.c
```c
/* SPDX-License-Identifier: Apache-2.0 */

#include "ivc_transport.h"

#include <zephyr/kernel.h>
#include <zephyr/sys/printk.h>

#include <errno.h>
#include <stdint.h>

#define IVC_PUBLISHER_VM_ID 1U
#define IVC_CHANNEL_KEY 0x49564301U
#define IVC_SUBSCRIBE_RETRY_MS 100U

int robot_ivc_subscribe(struct robot_ivc *ivc)
{
	uint64_t attempts = 0U;

	if (ivc == NULL) {
		return -EINVAL;
	}

	for (;;) {
		++attempts;
		ivc->channel = axivc_subscribe(IVC_PUBLISHER_VM_ID,
						 IVC_CHANNEL_KEY, 0);
		if (ivc->channel != NULL) {
			printk("ZEPHYR_IVC_READY publisher=%u key=0x%x attempts=%llu "
			       "transport=ivc-sdk\n",
			       IVC_PUBLISHER_VM_ID, IVC_CHANNEL_KEY, attempts);
			return 0;
		}

		if (attempts == 1U || attempts % 30U == 0U) {
			printk("ZEPHYR_IVC_WAIT attempts=%llu publisher=%u key=0x%x\n",
			       attempts, IVC_PUBLISHER_VM_ID, IVC_CHANNEL_KEY);
		}
		k_msleep(IVC_SUBSCRIBE_RETRY_MS);
	}
}

int robot_ivc_try_receive(struct robot_ivc *ivc, void *payload, size_t capacity,
				  size_t *length)
{
	int status;

	if (ivc == NULL || ivc->channel == NULL || payload == NULL ||
	    length == NULL) {
		return -EINVAL;
	}

	status = axivc_recv(ivc->channel, payload, capacity, length, 0);
	/* The current SDK converts an empty non-blocking receive to ETIMEDOUT.
	 * Preserve the robot controller's established try-receive contract until
	 * the SDK timeout API is standardized in a separate change.
	 */
	if (status == -ETIMEDOUT) {
		return -EAGAIN;
	}
	return status;
}

int robot_ivc_send(struct robot_ivc *ivc, const void *payload, size_t length,
		   int timeout_ms)
{
	if (ivc == NULL || ivc->channel == NULL || payload == NULL) {
		return -EINVAL;
	}
	return axivc_send(ivc->channel, payload, length, timeout_ms);
}

int robot_ivc_close(struct robot_ivc *ivc)
{
	int status;

	if (ivc == NULL || ivc->channel == NULL) {
		return 0;
	}
	status = axivc_close(ivc->channel);
	ivc->channel = NULL;
	return status;
}
```

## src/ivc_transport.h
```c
/* SPDX-License-Identifier: Apache-2.0 */

#ifndef ROBOT_IVC_TRANSPORT_H_
#define ROBOT_IVC_TRANSPORT_H_

#include <axivc/axivc.h>

#include <stddef.h>

struct robot_ivc {
	axivc_channel_t *channel;
};

/* Wait until Starry VM 1 publishes the robot perception channel. */
int robot_ivc_subscribe(struct robot_ivc *ivc);

/* Return 0 for one message, -EAGAIN when the ring is currently empty. */
int robot_ivc_try_receive(struct robot_ivc *ivc, void *payload, size_t capacity,
				  size_t *length);

int robot_ivc_send(struct robot_ivc *ivc, const void *payload, size_t length,
		   int timeout_ms);

int robot_ivc_close(struct robot_ivc *ivc);

#endif /* ROBOT_IVC_TRANSPORT_H_ */
```

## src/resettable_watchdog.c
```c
/* SPDX-License-Identifier: Apache-2.0 */

#include "resettable_watchdog.h"

#include <zephyr/logging/log.h>
#include <zephyr/sys/util.h>

LOG_MODULE_REGISTER(robot_watchdog_diag, LOG_LEVEL_DBG);

static void watchdog_work_handler(struct k_work *work)
{
	struct resettable_watchdog *watchdog =
		CONTAINER_OF(work, struct resettable_watchdog, work);
	const int64_t started_ms = k_uptime_get();

	LOG_DBG("ZEPHYR_DIAG component=watchdog event=work-enter uptime_ms=%lld",
		started_ms);
	watchdog->handler(watchdog->context);
	LOG_DBG("ZEPHYR_DIAG component=watchdog event=work-exit elapsed_ms=%lld",
		k_uptime_get() - started_ms);
}

static void watchdog_timer_expiry(struct k_timer *timer)
{
	struct resettable_watchdog *watchdog = k_timer_user_data_get(timer);

	/* UART and controller state changes are not IRQ-safe.  Move expiry
	 * handling to the system workqueue's thread context.
	 */
	const int submit_result = k_work_submit(&watchdog->work);
	LOG_DBG("ZEPHYR_DIAG component=watchdog event=timer-expiry submit=%d "
		"uptime_ms=%lld",
		submit_result, k_uptime_get());
}

void resettable_watchdog_init(struct resettable_watchdog *watchdog,
			      resettable_watchdog_handler_t handler,
			      void *context)
{
	watchdog->handler = handler;
	watchdog->context = context;
	k_work_init(&watchdog->work, watchdog_work_handler);
	k_timer_init(&watchdog->timer, watchdog_timer_expiry, NULL);
	k_timer_user_data_set(&watchdog->timer, watchdog);
}

void resettable_watchdog_restart(struct resettable_watchdog *watchdog,
				 uint32_t timeout_ms)
{
	k_timer_start(&watchdog->timer, K_MSEC(timeout_ms), K_NO_WAIT);
}

void resettable_watchdog_stop(struct resettable_watchdog *watchdog)
{
	k_timer_stop(&watchdog->timer);
}
```

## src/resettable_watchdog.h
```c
/* SPDX-License-Identifier: Apache-2.0 */

#ifndef RESETTABLE_WATCHDOG_H_
#define RESETTABLE_WATCHDOG_H_

#include <zephyr/kernel.h>

#include <stdint.h>

typedef void (*resettable_watchdog_handler_t)(void *context);

struct resettable_watchdog {
	struct k_timer timer;
	struct k_work work;
	resettable_watchdog_handler_t handler;
	void *context;
};

void resettable_watchdog_init(struct resettable_watchdog *watchdog,
			      resettable_watchdog_handler_t handler,
			      void *context);
void resettable_watchdog_restart(struct resettable_watchdog *watchdog,
				 uint32_t timeout_ms);
void resettable_watchdog_stop(struct resettable_watchdog *watchdog);

#endif /* RESETTABLE_WATCHDOG_H_ */
```

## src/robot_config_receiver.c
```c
/* SPDX-License-Identifier: Apache-2.0 */

#include "robot_config_receiver.h"

#include <string.h>

static uint16_t required_chunks(uint32_t size)
{
	return (uint16_t)((size + ROBOT_CONFIG_CHUNK_PAYLOAD_SIZE - 1U) /
			  ROBOT_CONFIG_CHUNK_PAYLOAD_SIZE);
}

static void make_response(const struct robot_config_message_v1 *message,
			  struct robot_config_message_v1 *response,
			  uint8_t type, uint8_t status, uint16_t expected)
{
	memset(response, 0, sizeof(*response));
	response->magic = ROBOT_CONFIG_MESSAGE_MAGIC;
	response->version = ROBOT_CONFIG_MESSAGE_VERSION;
	response->type = type;
	response->status = status;
	response->session_id = message->session_id;
	response->chunk_index = message->chunk_index;
	response->chunk_count = expected;
	response->config_size = message->config_size;
	response->config_crc32 = message->config_crc32;
}

void robot_config_make_rejected(
	const struct robot_config_message_v1 *message,
	struct robot_config_message_v1 *response,
	uint8_t status, uint16_t expected_chunk)
{
	make_response(message, response, ROBOT_CONFIG_REJECTED, status,
		      expected_chunk);
}

static bool valid_runtime_config(const struct robot_runtime_config_v1 *config)
{
	if (config->magic != ROBOT_RUNTIME_CONFIG_MAGIC ||
	    config->version != ROBOT_RUNTIME_CONFIG_VERSION ||
	    config->size != sizeof(*config) ||
	    config->motion_speed_level < 1U || config->motion_speed_level > 4U ||
	    config->ball_target_size < 50U || config->ball_target_size > 400U ||
	    config->ball_size_tolerance > 100U ||
	    config->ball_center_tolerance > 160U ||
	    config->ball_stable_frames == 0U || config->ball_stable_frames > 30U ||
	    config->bucket_target_size < 50U || config->bucket_target_size > 700U ||
	    config->bucket_center_tolerance < 5U ||
	    config->bucket_center_tolerance > 100U ||
	    config->bucket_stable_frames == 0U ||
	    config->bucket_stable_frames > 30U ||
	    config->gripper_range_min >= config->gripper_range_max ||
	    config->gripper_range_max > 4095U ||
	    config->gripper_hold_percent > 100U) {
		return false;
	}
	for (size_t pose = 0; pose < ROBOT_POSE_COUNT; ++pose) {
		for (size_t joint = 0; joint < ROBOT_JOINT_COUNT; ++joint) {
			if (config->poses[pose][joint] > 4095U) {
				return false;
			}
		}
		const uint16_t gripper = config->poses[pose][ROBOT_JOINT_COUNT - 1U];
		if (gripper < config->gripper_range_min ||
		    gripper > config->gripper_range_max) {
			return false;
		}
	}
	const uint16_t *speeds = &config->ball_search_speed;
	for (size_t index = 0; index < 10U; ++index) {
		if (speeds[index] == 0U || speeds[index] > 100U) {
			return false;
		}
	}
	return true;
}

void robot_config_receiver_init(struct robot_config_receiver *receiver)
{
	memset(receiver, 0, sizeof(*receiver));
}

bool robot_config_is_message(const void *payload, size_t length)
{
	if (payload == NULL || length != sizeof(struct robot_config_message_v1)) {
		return false;
	}
	const struct robot_config_message_v1 *message = payload;
	return message->magic == ROBOT_CONFIG_MESSAGE_MAGIC &&
	       message->version == ROBOT_CONFIG_MESSAGE_VERSION;
}

void robot_config_receiver_handle(
	struct robot_config_receiver *receiver,
	const struct robot_config_message_v1 *message,
	struct robot_config_message_v1 *response,
	struct robot_runtime_config_v1 *output,
	bool *applied)
{
	*applied = false;
	if (message->magic != ROBOT_CONFIG_MESSAGE_MAGIC ||
	    message->version != ROBOT_CONFIG_MESSAGE_VERSION) {
		make_response(message, response, ROBOT_CONFIG_REJECTED,
			      ROBOT_CONFIG_STATUS_INVALID_MESSAGE,
			      receiver->expected_chunk);
		return;
	}

	if (message->type == ROBOT_CONFIG_BEGIN) {
		const uint16_t chunks = required_chunks(message->config_size);
		if (message->config_size != sizeof(struct robot_runtime_config_v1) ||
		    message->chunk_count != chunks || chunks == 0U) {
			make_response(message, response, ROBOT_CONFIG_REJECTED,
				      ROBOT_CONFIG_STATUS_INVALID_SIZE, 0U);
			return;
		}
		memset(receiver->bytes, 0, sizeof(receiver->bytes));
		receiver->session_id = message->session_id;
		receiver->config_crc32 = message->config_crc32;
		receiver->chunk_count = chunks;
		receiver->expected_chunk = 0U;
		receiver->receiving = true;
		make_response(message, response, ROBOT_CONFIG_ACK,
			      ROBOT_CONFIG_STATUS_OK, 0U);
		return;
	}

	if (message->type == ROBOT_CONFIG_COMMIT &&
	    message->session_id == receiver->applied_session_id &&
	    message->config_crc32 == receiver->applied_crc32) {
		make_response(message, response, ROBOT_CONFIG_APPLIED,
			      ROBOT_CONFIG_STATUS_OK, message->chunk_count);
		return;
	}

	if (!receiver->receiving || message->session_id != receiver->session_id) {
		make_response(message, response, ROBOT_CONFIG_REJECTED,
			      ROBOT_CONFIG_STATUS_WRONG_SESSION,
			      receiver->expected_chunk);
		return;
	}

	if (message->type == ROBOT_CONFIG_CHUNK) {
		if (message->chunk_index > receiver->expected_chunk ||
		    message->chunk_index >= receiver->chunk_count) {
			make_response(message, response, ROBOT_CONFIG_REJECTED,
				      ROBOT_CONFIG_STATUS_OUT_OF_ORDER,
				      receiver->expected_chunk);
			return;
		}
		if (message->chunk_index < receiver->expected_chunk) {
			make_response(message, response, ROBOT_CONFIG_ACK,
				      ROBOT_CONFIG_STATUS_OK,
				      receiver->expected_chunk);
			return;
		}
		const size_t offset =
			(size_t)message->chunk_index * ROBOT_CONFIG_CHUNK_PAYLOAD_SIZE;
		const size_t remaining = sizeof(receiver->bytes) - offset;
		const size_t expected_size =
			remaining < ROBOT_CONFIG_CHUNK_PAYLOAD_SIZE ? remaining :
			ROBOT_CONFIG_CHUNK_PAYLOAD_SIZE;
		if (message->payload_size != expected_size) {
			make_response(message, response, ROBOT_CONFIG_REJECTED,
				      ROBOT_CONFIG_STATUS_INVALID_SIZE,
				      receiver->expected_chunk);
			return;
		}
		memcpy(receiver->bytes + offset, message->payload, expected_size);
		++receiver->expected_chunk;
		make_response(message, response, ROBOT_CONFIG_ACK,
			      ROBOT_CONFIG_STATUS_OK, receiver->expected_chunk);
		return;
	}

	if (message->type == ROBOT_CONFIG_COMMIT) {
		if (receiver->expected_chunk != receiver->chunk_count) {
			make_response(message, response, ROBOT_CONFIG_REJECTED,
				      ROBOT_CONFIG_STATUS_OUT_OF_ORDER,
				      receiver->expected_chunk);
			return;
		}
		const uint32_t crc = robot_config_crc32(receiver->bytes,
						       sizeof(receiver->bytes));
		if (crc != receiver->config_crc32 || crc != message->config_crc32) {
			make_response(message, response, ROBOT_CONFIG_REJECTED,
				      ROBOT_CONFIG_STATUS_CRC_MISMATCH,
				      receiver->expected_chunk);
			return;
		}
		struct robot_runtime_config_v1 candidate;
		memcpy(&candidate, receiver->bytes, sizeof(candidate));
		if (!valid_runtime_config(&candidate)) {
			make_response(message, response, ROBOT_CONFIG_REJECTED,
				      ROBOT_CONFIG_STATUS_INVALID_CONFIG,
				      receiver->expected_chunk);
			return;
		}
		memcpy(output, &candidate, sizeof(*output));
		*applied = true;
		make_response(message, response, ROBOT_CONFIG_APPLIED,
			      ROBOT_CONFIG_STATUS_OK, receiver->expected_chunk);
		return;
	}

	make_response(message, response, ROBOT_CONFIG_REJECTED,
		      ROBOT_CONFIG_STATUS_INVALID_MESSAGE,
		      receiver->expected_chunk);
}

void robot_config_receiver_mark_applied(
	struct robot_config_receiver *receiver)
{
	receiver->applied_session_id = receiver->session_id;
	receiver->applied_crc32 = receiver->config_crc32;
	receiver->receiving = false;
}
```

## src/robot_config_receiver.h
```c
/* SPDX-License-Identifier: Apache-2.0 */

#ifndef ROBOT_CONFIG_RECEIVER_H_
#define ROBOT_CONFIG_RECEIVER_H_

#include "robot_runtime_config_v1.h"

#include <stdbool.h>
#include <stddef.h>
#include <stdint.h>

#ifdef __cplusplus
extern "C" {
#endif

struct robot_config_receiver {
	uint8_t bytes[sizeof(struct robot_runtime_config_v1)];
	uint32_t session_id;
	uint32_t config_crc32;
	uint16_t chunk_count;
	uint16_t expected_chunk;
	uint32_t applied_session_id;
	uint32_t applied_crc32;
	bool receiving;
};

void robot_config_receiver_init(struct robot_config_receiver *receiver);

bool robot_config_is_message(const void *payload, size_t length);

void robot_config_make_rejected(
	const struct robot_config_message_v1 *message,
	struct robot_config_message_v1 *response,
	uint8_t status, uint16_t expected_chunk);

/* Handle one configuration message and always produce an ACK/APPLIED/REJECTED
 * response. On a successful COMMIT, writes the validated configuration to
 * output and sets applied=true.
 */
void robot_config_receiver_handle(
	struct robot_config_receiver *receiver,
	const struct robot_config_message_v1 *message,
	struct robot_config_message_v1 *response,
	struct robot_runtime_config_v1 *output,
	bool *applied);

/* Record a validated COMMIT only after the controller accepted the candidate.
 * This makes a retried COMMIT truthful when hardware preparation fails.
 */
void robot_config_receiver_mark_applied(
	struct robot_config_receiver *receiver);

#ifdef __cplusplus
}
#endif

#endif /* ROBOT_CONFIG_RECEIVER_H_ */
```
